# HTNB32L-XXX register map
File version: 0.9
CPU: CM3 r0p0, little endian, no MPU, no FPU, 3 interrupt priority bits
Registers are 32-bit, read-write, reset 0x0 unless marked. A register's access mark holds for its fields unless they carry their own. Offsets are from the block's base; [hi:lo] are bit positions; 'fields as' and 'values as' point back to an identical list.

## IOCON (part 1 of 3) — IOCON pin configuration
Base 0x4002C000
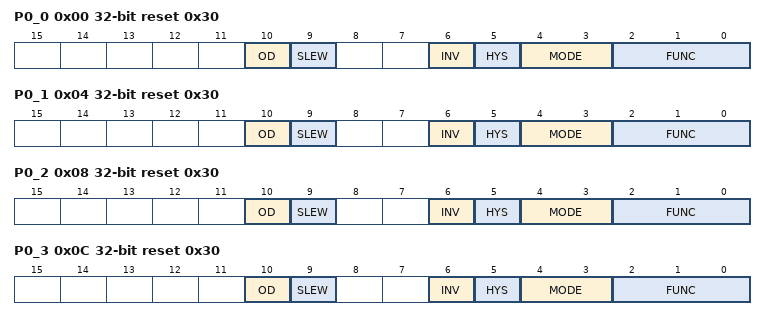
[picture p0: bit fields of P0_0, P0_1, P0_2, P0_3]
0x00 P0_0 reset 0x30 — I/O configuration register for pin P0[0]
  [10] OD — Open-drain mode.
    0=DISABLE; 1=ENABLED (Open-drain mode enabled. This is not a true open-drain mode. Input cannot be pulled up above VDD.)
  [9] SLEW — Driver slew rate
    0=STANDARD (Standard mode, output slew rate control is enabled. More outputs can be switched simultaneously.); 1=FAST (Fast mode, slew rate control is disabled. Refer to the appropriate specific device data sheet for details.)
  [6] INV — Invert input
    0=INPUT_NOT_INVERTED (Input not inverted (HIGH on pin reads as 1, LOW on pin reads as 0).); 1=INPUT_INVERTED_HIGH (Input inverted (HIGH on pin reads as 0, LOW on pin reads as 1).)
  [5] HYS — Hysteresis.
    0=DISABLE; 1=ENABLE
  [4:3] MODE — Selects function mode (on-chip pull-up/pull-down resistor control).
    0=INACTIVE (Inactive (no pull-down/pull-up resistor enabled).); 1=PULLDOWN_EN (Pull-down resistor enabled.); 2=PULLUP_EN (Pull-up resistor enabled.); 3=REPEATER_MODE
  [2:0] FUNC — Selects pin function for pin P0[0]
    0=P0_0 (General purpose digital input/output pin.); 1=CAN_RD1 (CAN1 receiver input.); 2=U3_TXD (Transmitter output for UART3.); 3=I2C1_SDA (I2C1 data input/output(this pin does not use a specialized I2C pad).); 4=U0_TXD (Transmitter output for UART0.)
0x04 P0_1 reset 0x30 — I/O configuration register for pin P0[1]
  [10] OD — Open-drain mode.
    values as P0_0.OD
  [9] SLEW — Driver slew rate
    values as P0_0.SLEW
  [6] INV — Invert input
    values as P0_0.INV
  [5] HYS — Hysteresis.
    0=DISABLE; 1=ENABLE
  [4:3] MODE — Selects function mode (on-chip pull-up/pull-down resistor control).
    values as P0_0.MODE
  [2:0] FUNC — Selects pin function for pin P0[1]
    0=P0_1 (General purpose digital input/output pin.); 1=CAN_TD1 (CAN1 transmitter output.); 2=U3_RXD (Receiver input for UART3.); 3=I2C1_SCL (I2C1 clock input/output (this pin does not use a specialized I2C pad).); 4=U0_RXD (Receiver input for UART0.)
0x08 P0_2 reset 0x30 — I/O configuration register for pin P0[2]
  [10] OD — Open-drain mode.
    values as P0_0.OD
  [9] SLEW — Driver slew rate
    values as P0_0.SLEW
  [6] INV — Invert input
    values as P0_0.INV
  [5] HYS — Hysteresis.
    0=DISABLE; 1=ENABLE
  [4:3] MODE — Selects function mode (on-chip pull-up/pull-down resistor control).
    values as P0_0.MODE
  [2:0] FUNC — Selects pin function for pin P0[2]
    0=P0_2 (General purpose digital input/output pin.); 1=U0_TXD (Transmitter output for UART0.); 2=U3_TXD (Transmitter output for UART3.)
0x0C P0_3 reset 0x30 — I/O configuration register for pin P0[3]
  [10] OD — Open-drain mode.
    values as P0_0.OD
  [9] SLEW — Driver slew rate
    values as P0_0.SLEW
  [6] INV — Invert input
    values as P0_0.INV
  [5] HYS — Hysteresis.
    0=DISABLE; 1=ENABLE
  [4:3] MODE — Selects function mode (on-chip pull-up/pull-down resistor control).
    values as P0_0.MODE
  [2:0] FUNC — Selects pin function for pin P0[3]
    0=P0_3 (General purpose digital input/output pin.); 1=U0_RXD (Receiver input for UART0.); 2=U3_RXD (Receiver input for UART3.)
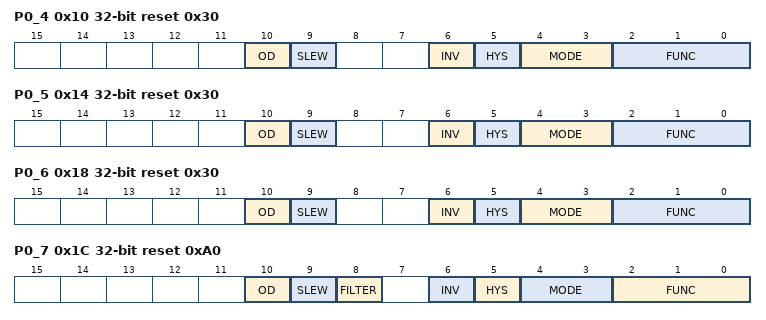
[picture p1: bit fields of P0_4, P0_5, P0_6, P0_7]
0x10 P0_4 reset 0x30 — I/O configuration register for pin P0[4]
  [10] OD — Open-drain mode.
    values as P0_0.OD
  [9] SLEW — Driver slew rate
    values as P0_0.SLEW
  [6] INV — Invert input
    values as P0_0.INV
  [5] HYS — Hysteresis.
    0=DISABLE; 1=ENABLE
  [4:3] MODE — Selects function mode (on-chip pull-up/pull-down resistor control).
    values as P0_0.MODE
  [2:0] FUNC — Selects pin function for pin P0[4]
    0=P0_4 (General purpose digital input/output pin.); 1=I2S_RX_SCK (I2S Receive clock. It is driven by the master and received by the slave. Corresponds to the signal SCK in the I2S-bus specification.); 2=CAN_RD2 (CAN2 receiver input.); 3=T2_CAP0 (Capture input for Timer 2, channel 0.); 7=LCD_VD_0 (LCD data.)
0x14 P0_5 reset 0x30 — I/O configuration register for pin P0[5]
  [10] OD — Open-drain mode.
    values as P0_0.OD
  [9] SLEW — Driver slew rate
    values as P0_0.SLEW
  [6] INV — Invert input
    values as P0_0.INV
  [5] HYS — Hysteresis.
    0=DISABLE; 1=ENABLE
  [4:3] MODE — Selects function mode (on-chip pull-up/pull-down resistor control).
    values as P0_0.MODE
  [2:0] FUNC — Selects pin function for pin P0[5]
    0=P0_5 (General purpose digital input/output pin.); 1=I2S_RX_WS (I2S Receive word select. It is driven by the master and received by the slave. Corresponds to the signal WS in the I2S-bus specification.); 2=CAN_TD2 (CAN2 transmitter output.); 3=T2_CAP1 (Capture input for Timer 2, channel 1.); 7=LCD_VD_1 (LCD data.)
0x18 P0_6 reset 0x30 — I/O configuration register for pin P0[6]
  [10] OD — Open-drain mode.
    values as P0_0.OD
  [9] SLEW — Driver slew rate
    values as P0_0.SLEW
  [6] INV — Invert input
    values as P0_0.INV
  [5] HYS — Hysteresis.
    0=DISABLE; 1=ENABLE
  [4:3] MODE — Selects function mode (on-chip pull-up/pull-down resistor control).
    values as P0_0.MODE
  [2:0] FUNC — Selects pin function for pin P0[6]
    0=P0_6 (General purpose digital input/output pin.); 1=I2S_RX_SDA (I2S Receive data. It is driven by the transmitter and read by the receiver. Corresponds to the signal SD in the I2S-bus specification.); 2=SSP1_SSEL (Slave Select for SSP1.); 3=T2_MAT0 (Match output for Timer 2, channel 0.); 4=U1_RTS (Request to Send output for UART1. Can also be configured to be an RS-485/EIA-485 output enable signal for UART1.); 7=LCD_VD_8 (LCD data.)
0x1C P0_7 reset 0xA0 — I/O configuration register for pin P0[7]
  [10] OD — Open-drain mode.
    values as P0_0.OD
  [9] SLEW — Driver slew rate
    values as P0_0.SLEW
  [8] FILTER — Glitch filter control
    0=ENABLED (Noise pulses below approximately 10 ns are filtered out.); 1=DISABLED (No input filtering is done.)
  [6] INV — Invert input
    values as P0_0.INV
  [5] HYS — Hysteresis.
    0=DISABLE; 1=ENABLE
  [4:3] MODE — Selects function mode (on-chip pull-up/pull-down resistor control).
    values as P0_0.MODE
  [2:0] FUNC — Selects pin function for pin P0[7]
    0=P0_7 (General purpose digital input/output pin.); 1=I2S_TX_SCK (I2S transmit clock. It is driven by the master and received by the slave. Corresponds to the signal SCK in the I2S-bus specification.); 2=SSP1_SCK (Serial Clock for SSP1.); 3=T2_MAT1 (Match output for Timer 2, channel 1.); 4=RTC_EV0 (Event input 0 to Event Monitor/Recorder.); 7=LCD_VD_9 (LCD data.)
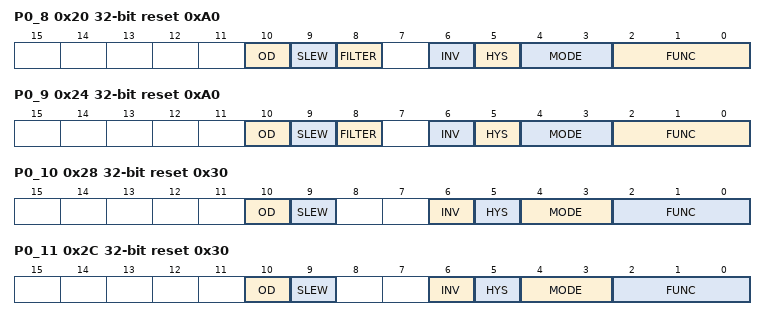
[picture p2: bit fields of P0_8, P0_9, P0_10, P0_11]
0x20 P0_8 reset 0xA0 — I/O configuration register for pin P0[8]
  [10] OD — Open-drain mode.
    values as P0_0.OD
  [9] SLEW — Driver slew rate
    values as P0_0.SLEW
  [8] FILTER — Glitch filter control
    values as P0_7.FILTER
  [6] INV — Invert input
    values as P0_0.INV
  [5] HYS — Hysteresis.
    0=DISABLE; 1=ENABLE
  [4:3] MODE — Selects function mode (on-chip pull-up/pull-down resistor control).
    values as P0_0.MODE
  [2:0] FUNC — Selects pin function for pin P0[8]
    0=P0_8 (General purpose digital input/output pin.); 1=I2S_TX_WS (I2S Transmit word select. It is driven by the master and received by the slave. Corresponds to the signal WS in the I2S-bus specification.); 2=SSP1_MISO (Master In Slave Out for SSP1.); 3=T2_MAT2 (Match output for Timer 2, channel 2.); 4=RTC_EV1 (Event input 1 to Event Monitor/Recorder.); 7=LCD_VD_16 (LCD data.)
0x24 P0_9 reset 0xA0 — I/O configuration register for pin P0[9]
  [10] OD — Open-drain mode.
    values as P0_0.OD
  [9] SLEW — Driver slew rate
    values as P0_0.SLEW
  [8] FILTER — Glitch filter control
    values as P0_7.FILTER
  [6] INV — Invert input
    values as P0_0.INV
  [5] HYS — Hysteresis.
    0=DISABLE; 1=ENABLE
  [4:3] MODE — Selects function mode (on-chip pull-up/pull-down resistor control).
    values as P0_0.MODE
  [2:0] FUNC — Selects pin function for pin P0[9]
    0=P0_9 (General purpose digital input/output pin.); 1=I2S_TX_SDA (I2S transmit data. It is driven by the transmitter and read by the receiver. Corresponds to the signal SD in the I2S-bus specification.); 2=SSP1_MOSI (Master Out Slave In for SSP1.); 3=T2_MAT3 (Match output for Timer 2, channel 3.); 4=RTC_EV2 (Event input 2 to Event Monitor/Recorder.); 7=LCD_VD_17 (LCD data.)
0x28 P0_10 reset 0x30 — I/O configuration register for pin P0[10]
  [10] OD — Open-drain mode.
    values as P0_0.OD
  [9] SLEW — Driver slew rate
    values as P0_0.SLEW
  [6] INV — Invert input
    values as P0_0.INV
  [5] HYS — Hysteresis.
    0=DISABLE; 1=ENABLE
  [4:3] MODE — Selects function mode (on-chip pull-up/pull-down resistor control).
    values as P0_0.MODE
  [2:0] FUNC — Selects pin function for pin P0[10]
    0=P0_10 (General purpose digital input/output pin.); 1=U2_TXD (Transmitter output for UART2.); 2=I2C2_SDA (I2C2 data input/output (this pin does not use a specialized I2C pad).); 3=T3_MAT0 (Match output for Timer 3, channel 0.)
0x2C P0_11 reset 0x30 — I/O configuration register for pin P0[11]
  [10] OD — Open-drain mode.
    values as P0_0.OD
  [9] SLEW — Driver slew rate
    values as P0_0.SLEW
  [6] INV — Invert input
    values as P0_0.INV
  [5] HYS — Hysteresis.
    0=DISABLE; 1=ENABLE
  [4:3] MODE — Selects function mode (on-chip pull-up/pull-down resistor control).
    values as P0_0.MODE
  [2:0] FUNC — Selects pin function for pin P0[11]
    0=P0_11 (General purpose digital input/output pin.); 1=U2_RXD (Receiver input for UART2.); 2=I2C2_SCL (I2C2 clock input/output (this pin does not use a specialized I2C pad).); 3=T3_MAT1 (Match output for Timer 3, channel 1.)
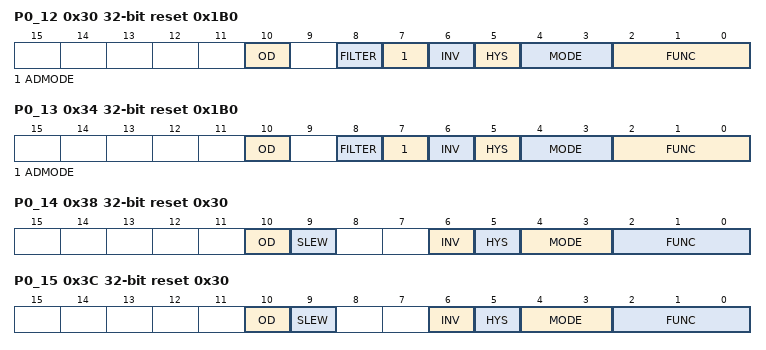
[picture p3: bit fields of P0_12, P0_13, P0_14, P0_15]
0x30 P0_12 reset 0x1B0 — I/O configuration register for pin P0[12]
  [10] OD — Open-drain mode.
    0=DISABLE; 1=ENABLED (Open-drain mode enabled. This is not a true open-drain mode.)
  [8] FILTER — Selects 10 ns input glitch filter.
    0=FILTER_DISABLED; 1=FILTER_ENABLED
  [7] ADMODE — Selects Analog/Digital mode.
    0=ANALOG_INPUT_MODE; 1=DIGITAL_FUNCTIONAL_M (Digital functional mode.)
  [6] INV — Invert input
    values as P0_0.INV
  [5] HYS — Hysteresis.
    0=DISABLE; 1=ENABLE
  [4:3] MODE — Selects function mode (on-chip pull-up/pull-down resistor control).
    values as P0_0.MODE
  [2:0] FUNC — Selects pin function for pin P0[12]
    0=P0_12 (General purpose digital input/output pin.); 1=USB_PPWR2 (Port Power enable signal for USB port 2.); 2=SSP1_MISO (Master In Slave Out for SSP1.); 3=ADC0_IN_6 (A/D converter 0, input 6. When configured as an ADC input, the digital function of the pin must be disabled.)
0x34 P0_13 reset 0x1B0 — I/O configuration register for pin P0[13]
  [10] OD — Open-drain mode.
    values as P0_12.OD
  [8] FILTER — Selects 10 ns input glitch filter.
    0=FILTER_DISABLED; 1=FILTER_ENABLED
  [7] ADMODE — Selects Analog/Digital mode.
    values as P0_12.ADMODE
  [6] INV — Invert input
    values as P0_0.INV
  [5] HYS — Hysteresis.
    0=DISABLE; 1=ENABLE
  [4:3] MODE — Selects function mode (on-chip pull-up/pull-down resistor control).
    values as P0_0.MODE
  [2:0] FUNC — Selects pin function for pin P0[13]
    0=P0_13 (General purpose digital input/output pin.); 1=USB_UP_LED2 (USB port 2 GoodLink LED indicator. It is LOW when the device is configured (non-control endpoints enabled), or when the host is enabled and has detected a device on the bus. It is HIGH when the device is not configured, or when host is enabled and has not detected a device on the bus, or during global suspend. It transitions between LOW and HIGH (flashes) when the host is enabled and detects activity on the bus.); 2=SSP1_MOSI (Master Out Slave In for SSP1.); 3=ADC0_IN_7 (A/D converter 0, input 7. When configured as an ADC input, the digital function of the pin must be disabled.)
0x38 P0_14 reset 0x30 — I/O configuration register for pin P0[14]
  [10] OD — Open-drain mode.
    values as P0_0.OD
  [9] SLEW — Driver slew rate
    values as P0_0.SLEW
  [6] INV — Invert input
    values as P0_0.INV
  [5] HYS — Hysteresis.
    0=DISABLE; 1=ENABLE
  [4:3] MODE — Selects function mode (on-chip pull-up/pull-down resistor control).
    values as P0_0.MODE
  [2:0] FUNC — Selects pin function for pin P0[14]
    0=P0_14 (General purpose digital input/output pin.); 1=USB_HSTEN2 (Host Enabled status for USB port 2.); 2=SSP1_SSEL (Slave Select for SSP1.); 3=USB_CONNECT2 (SoftConnect control for USB port 2. Signal used to switch an external 1.5 kW resistor under software control. Used with the SoftConnect USB feature.)
0x3C P0_15 reset 0x30 — I/O configuration register for pin P0[15]
  [10] OD — Open-drain mode.
    values as P0_0.OD
  [9] SLEW — Driver slew rate
    values as P0_0.SLEW
  [6] INV — Invert input
    values as P0_0.INV
  [5] HYS — Hysteresis.
    0=DISABLE; 1=ENABLE
  [4:3] MODE — Selects function mode (on-chip pull-up/pull-down resistor control).
    values as P0_0.MODE
  [2:0] FUNC — Selects pin function for pin P0[15]
    0=P0_15 (General purpose digital input/output pin.); 1=U1_TXD (Transmitter output for UART1.); 2=SSP0_SCK (Serial clock for SSP0.)
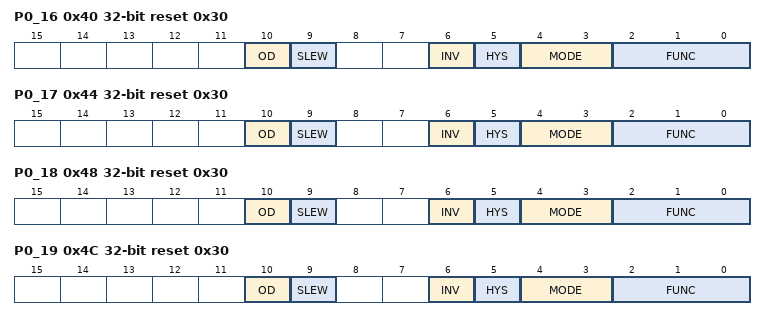
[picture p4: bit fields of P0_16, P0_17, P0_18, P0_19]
0x40 P0_16 reset 0x30 — I/O configuration register for pin P0[16]
  [10] OD — Open-drain mode.
    values as P0_0.OD
  [9] SLEW — Driver slew rate
    values as P0_0.SLEW
  [6] INV — Invert input
    values as P0_0.INV
  [5] HYS — Hysteresis.
    0=DISABLE; 1=ENABLE
  [4:3] MODE — Selects function mode (on-chip pull-up/pull-down resistor control).
    values as P0_0.MODE
  [2:0] FUNC — Selects pin function for pin P0[16]
    0=P0_16 (General purpose digital input/output pin.); 1=U1_RXD (Receiver input for UART1.); 2=SSP0_SSEL (Slave Select for SSP0.)
0x44 P0_17 reset 0x30 — I/O configuration register for pin P0[17]
  [10] OD — Open-drain mode.
    values as P0_0.OD
  [9] SLEW — Driver slew rate
    values as P0_0.SLEW
  [6] INV — Invert input
    values as P0_0.INV
  [5] HYS — Hysteresis.
    0=DISABLE; 1=ENABLE
  [4:3] MODE — Selects function mode (on-chip pull-up/pull-down resistor control).
    values as P0_0.MODE
  [2:0] FUNC — Selects pin function for pin P0[17]
    0=P0_17 (General purpose digital input/output pin.); 1=U1_CTS (Clear to Send input for UART1.); 2=SSP0_MISO (Master In Slave Out for SSP0.)
0x48 P0_18 reset 0x30 — I/O configuration register for pin P0[18]
  [10] OD — Open-drain mode.
    values as P0_0.OD
  [9] SLEW — Driver slew rate
    values as P0_0.SLEW
  [6] INV — Invert input
    values as P0_0.INV
  [5] HYS — Hysteresis.
    0=DISABLE; 1=ENABLE
  [4:3] MODE — Selects function mode (on-chip pull-up/pull-down resistor control).
    values as P0_0.MODE
  [2:0] FUNC — Selects pin function for pin P0[18]
    0=P0_18 (General purpose digital input/output pin.); 1=U1_DCD (Data Carrier Detect input for UART1.); 2=SSP0_MOSI (Master Out Slave In for SSP0.)
0x4C P0_19 reset 0x30 — I/O configuration register for pin P0[19]
  [10] OD — Open-drain mode.
    values as P0_0.OD
  [9] SLEW — Driver slew rate
    values as P0_0.SLEW
  [6] INV — Invert input
    values as P0_0.INV
  [5] HYS — Hysteresis.
    0=DISABLE; 1=ENABLE
  [4:3] MODE — Selects function mode (on-chip pull-up/pull-down resistor control).
    values as P0_0.MODE
  [2:0] FUNC — Selects pin function for pin P0[19]
    0=P0_19 (General purpose digital input/output pin.); 1=U1_DSR (Data Set Ready input for UART1.); 2=SD_CLK (Clock output line for SD card interface.); 3=I2C1_SDA (I2C1 data input/output (this pin does not use a specialized I2C pad).)
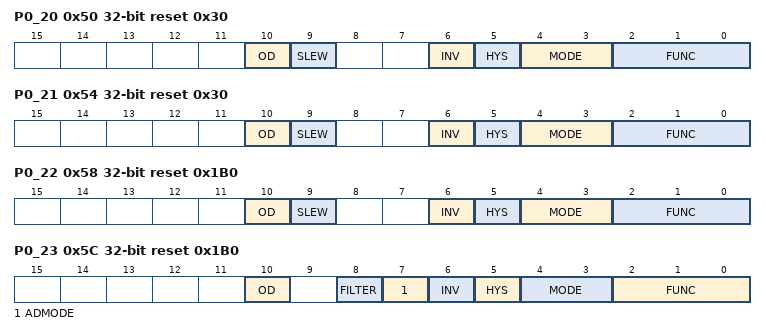
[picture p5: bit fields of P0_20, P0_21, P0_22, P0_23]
0x50 P0_20 reset 0x30 — I/O configuration register for pin P0[20]
  [10] OD — Open-drain mode.
    values as P0_0.OD
  [9] SLEW — Driver slew rate
    values as P0_0.SLEW
  [6] INV — Invert input
    values as P0_0.INV
  [5] HYS — Hysteresis.
    0=DISABLE; 1=ENABLE
  [4:3] MODE — Selects function mode (on-chip pull-up/pull-down resistor control).
    values as P0_0.MODE
  [2:0] FUNC — Selects pin function for pin P0[20]
    0=P0_20 (General purpose digital input/output pin.); 1=U1_DTR (Data Terminal Ready output for UART1. Can also be configured to be an RS-485/EIA-485 output enable signal for UART1.); 2=SD_CMD (Command line for SD card interface.); 3=I2C1_SCL (I2C1 clock input/output (this pin does not use a specialized I2C pad).)
0x54 P0_21 reset 0x30 — I/O configuration register for pin P0[21]
  [10] OD — Open-drain mode.
    values as P0_0.OD
  [9] SLEW — Driver slew rate
    values as P0_0.SLEW
  [6] INV — Invert input
    values as P0_0.INV
  [5] HYS — Hysteresis.
    0=DISABLE; 1=ENABLE
  [4:3] MODE — Selects function mode (on-chip pull-up/pull-down resistor control).
    values as P0_0.MODE
  [2:0] FUNC — Selects pin function for pin P0[21]
    0=P0_21 (General purpose digital input/output pin.); 1=U1_RI (Ring Indicator input for UART1.); 2=SD_PWR (Power Supply Enable for external SD card power supply.); 3=U4_OE (RS-485/EIA-485 output enable signal for UART4.); 4=CAN_RD1 (CAN1 receiver input.); 5=U4_SCLK (USART 4 clock input or output in synchronous mode.)
0x58 P0_22 reset 0x1B0 — I/O configuration register for pin P0[22]
  [10] OD — Open-drain mode.
    values as P0_0.OD
  [9] SLEW — Driver slew rate
    values as P0_0.SLEW
  [6] INV — Invert input
    values as P0_0.INV
  [5] HYS — Hysteresis.
    0=DISABLE; 1=ENABLE
  [4:3] MODE — Selects function mode (on-chip pull-up/pull-down resistor control).
    values as P0_0.MODE
  [2:0] FUNC — Selects pin function for pin P0[22]
    0=P0_22 (General purpose digital input/output pin.); 1=U1_RTS (Request to Send output for UART1. Can also be configured to be an RS-485/EIA-485 output enable signal for UART1.); 2=SD_DAT_0 (Data line 0 for SD card interface.); 3=U4_TXD (Transmitter output for USART4 (input/output in smart card mode).); 4=CAN_TD1 (CAN1 transmitter output.)
0x5C P0_23 reset 0x1B0 — I/O configuration register for pin P0[23]
  [10] OD — Open-drain mode.
    values as P0_12.OD
  [8] FILTER — Selects 10 ns input glitch filter.
    0=FILTER_DISABLED; 1=FILTER_ENABLED
  [7] ADMODE — Selects Analog/Digital mode.
    values as P0_12.ADMODE
  [6] INV — Invert input
    values as P0_0.INV
  [5] HYS — Hysteresis.
    0=DISABLE; 1=ENABLE
  [4:3] MODE — Selects function mode (on-chip pull-up/pull-down resistor control).
    values as P0_0.MODE
  [2:0] FUNC — Selects pin function for pin P0[23]
    0=P0_23 (General purpose digital input/output pin.); 1=ADC0_IN_0 (A/D converter 0, input 0. When configured as an ADC input, the digital function of the pin must be disabled.); 2=I2S_RX_SCK (Receive Clock. It is driven by the master and received by the slave. Corresponds to the signal SCK in the I2S-bus specification.); 3=T3_CAP0 (Capture input for Timer 3, channel 0.)
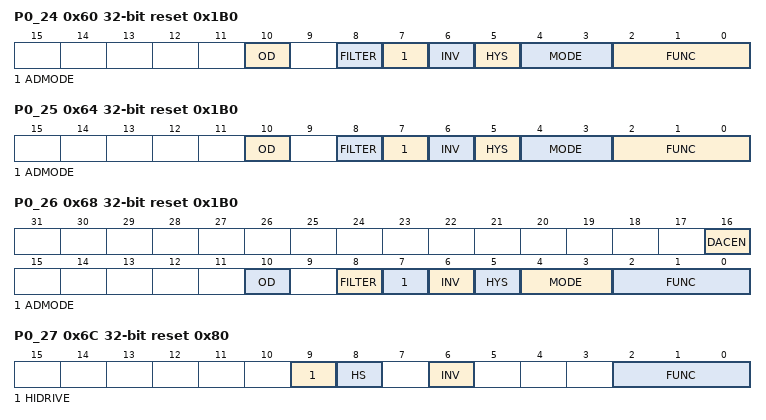
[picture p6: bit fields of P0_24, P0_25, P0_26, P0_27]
0x60 P0_24 reset 0x1B0 — I/O configuration register for pin P0[24]
  [10] OD — Open-drain mode.
    values as P0_12.OD
  [8] FILTER — Selects 10 ns input glitch filter.
    0=FILTER_DISABLED; 1=FILTER_ENABLED
  [7] ADMODE — Selects Analog/Digital mode.
    values as P0_12.ADMODE
  [6] INV — Invert input
    values as P0_0.INV
  [5] HYS — Hysteresis.
    0=DISABLE; 1=ENABLE
  [4:3] MODE — Selects function mode (on-chip pull-up/pull-down resistor control).
    values as P0_0.MODE
  [2:0] FUNC — Selects pin function for pin P0[24]
    0=P0_24 (General purpose digital input/output pin.); 1=ADC0_IN_1 (A/D converter 0, input 1. When configured as an ADC input, the digital function of the pin must be disabled.); 2=I2S_RX_WS (Receive Word Select. It is driven by the master and received by the slave. Corresponds to the signal WS in the I2S-bus specification.); 3=T3_CAP1 (Capture input for Timer 3, channel 1.)
0x64 P0_25 reset 0x1B0 — I/O configuration register for pin P0[25]
  [10] OD — Open-drain mode.
    values as P0_12.OD
  [8] FILTER — Selects 10 ns input glitch filter.
    0=FILTER_DISABLED; 1=FILTER_ENABLED
  [7] ADMODE — Selects Analog/Digital mode.
    values as P0_12.ADMODE
  [6] INV — Invert input
    values as P0_0.INV
  [5] HYS — Hysteresis.
    0=DISABLE; 1=ENABLE
  [4:3] MODE — Selects function mode (on-chip pull-up/pull-down resistor control).
    values as P0_0.MODE
  [2:0] FUNC — Selects pin function for pin P0[25]
    0=P0_25 (General purpose digital input/output pin.); 1=ADC0_IN_2 (A/D converter 0, input 2. When configured as an ADC input, the digital function of the pin must be disabled.); 2=I2S_RX_SDA (Receive data. It is driven by the transmitter and read by the receiver. Corresponds to the signal SD in the I2S-bus specification.); 3=U3_TXD (Transmitter output for UART3.)
0x68 P0_26 reset 0x1B0 — I/O configuration register for pin P0[26]
  [16] DACEN — DAC output enable.
    0=DISABLE (DAC disable.); 1=ENABLE (DAC enable.)
  [10] OD — Open-drain mode.
    values as P0_12.OD
  [8] FILTER — Selects 10 ns input glitch filter.
    0=FILTER_DISABLED; 1=FILTER_ENABLED
  [7] ADMODE — Selects Analog/Digital mode.
    values as P0_12.ADMODE
  [6] INV — Invert input
    values as P0_0.INV
  [5] HYS — Hysteresis.
    0=DISABLE; 1=ENABLE
  [4:3] MODE — Selects function mode (on-chip pull-up/pull-down resistor control).
    values as P0_0.MODE
  [2:0] FUNC — Selects pin function for pin P0[26]
    0=P0_26 (General purpose digital input/output pin.); 1=ADC0_IN_3 (A/D converter 0, input 3. When configured as an ADC input, the digital function of the pin must be disabled.); 2=DAC_OUT (D/A converter output. When configured as the DAC output, the digital function of the pin must be disabled.); 3=U3_RXD (Receiver input for UART3.)
0x6C P0_27 reset 0x80 — I/O configuration register for pin P0[27]
  [9] HIDRIVE — Controls sink current capability of the pin, only for P5[2] and P5[3].
    0=LOWDRIVE (Output drive sink is 4 mA. This is sufficient for standard and fast mode I2C.); 1=HIGHDRIVE (Output drive sink is 20 mA. This is needed for Fast Mode Plus I2C. Refer to the appropriate specific device data sheet for details.)
  [8] HS — Configures I2C features for standard mode, fast mode, and Fast Mode Plus operation.
    0=ENABLED (I2C 50ns glitch filter and slew rate control enabled.); 1=DISABLED (I2C 50ns glitch filter and slew rate control disabled.)
  [6] INV — Invert input
    values as P0_0.INV
  [2:0] FUNC — Selects pin function for pin P0[27]
    0=P0_27 (General purpose digital input/output pin.); 1=I2C0_SDA (I2C0 data input/output. (This pin uses a specialized I2C pad).); 2=USB_SDA1 (I2C serial data for communication with an external USB transceiver.)
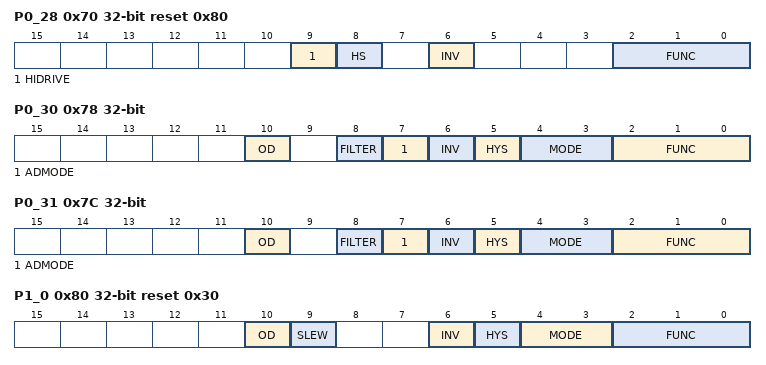
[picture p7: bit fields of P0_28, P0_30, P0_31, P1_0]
0x70 P0_28 reset 0x80 — I/O configuration register for pin P0[28]
  [9] HIDRIVE — Controls sink current capability of the pin, only for P5[2] and P5[3].
    values as P0_27.HIDRIVE
  [8] HS — Configures I2C features for standard mode, fast mode, and Fast Mode Plus operation.
    values as P0_27.HS
  [6] INV — Invert input
    values as P0_0.INV
  [2:0] FUNC — Selects pin function for pin P0[28]
    0=P0_28 (General purpose digital input/output pin.); 1=I2C0_SCL (I2C0 clock input/output (this pin uses a specialized I2C pad.); 2=USB_SCL1 (I2C serial clock for communication with an external USB transceiver.)
0x74 P0_29 — I/O configuration register for pin P0[29]
  [2:0] FUNC — Selects pin function for pin P0[29]
    0=P0_29 (General purpose digital input/output pin.); 1=USB_DP1 (USB port 1 bidirectional D+ line.); 2=EINT0 (External interrupt 0 input.)
0x78 P0_30 — I/O configuration register for pin P0[30]
  [10] OD — Open-drain mode.
    values as P0_12.OD
  [8] FILTER — Selects 10 ns input glitch filter.
    0=FILTER_DISABLED; 1=FILTER_ENABLED
  [7] ADMODE — Selects Analog/Digital mode.
    values as P0_12.ADMODE
  [6] INV — Invert input
    values as P0_0.INV
  [5] HYS — Hysteresis.
    0=DISABLE; 1=ENABLE
  [4:3] MODE — Selects function mode (on-chip pull-up/pull-down resistor control).
    values as P0_0.MODE
  [2:0] FUNC — Selects pin function for pin P0[30]
    0=P0_30 (General purpose digital input/output pin.); 1=USB_DM1 (USB port 1 bidirectional D- line.); 2=EINT1 (External interrupt 1 input.)
0x7C P0_31 — I/O configuration register for pin P0[31]
  [10] OD — Open-drain mode.
    values as P0_12.OD
  [8] FILTER — Selects 10 ns input glitch filter.
    0=FILTER_DISABLED; 1=FILTER_ENABLED
  [7] ADMODE — Selects Analog/Digital mode.
    values as P0_12.ADMODE
  [6] INV — Invert input
    values as P0_0.INV
  [5] HYS — Hysteresis.
    0=DISABLE; 1=ENABLE
  [4:3] MODE — Selects function mode (on-chip pull-up/pull-down resistor control).
    values as P0_0.MODE
  [2:0] FUNC — Selects pin function for pin P0[31]
    0=P0_31 (General purpose digital input/output pin.); 1=USB_DP2 (USB port 2 bidirectional D+ line.)
0x80 P1_0 reset 0x30 — I/O configuration register for pin P1[0]
  [10] OD — Open-drain mode.
    values as P0_0.OD
  [9] SLEW — Driver slew rate
    values as P0_0.SLEW
  [6] INV — Invert input
    values as P0_0.INV
  [5] HYS — Hysteresis.
    0=DISABLE; 1=ENABLE
  [4:3] MODE — Selects function mode (on-chip pull-up/pull-down resistor control).
    values as P0_0.MODE
  [2:0] FUNC — Selects pin function for pin P1[0]
    0=P1_0 (General purpose digital input/output pin.); 1=ENET_TXD0 (Ethernet transmit data 0 (RMII/MII interface).); 3=T3_CAP1 (Capture input for Timer 3, channel 1.); 4=SSP2_SCK (Serial clock for SSP2.)
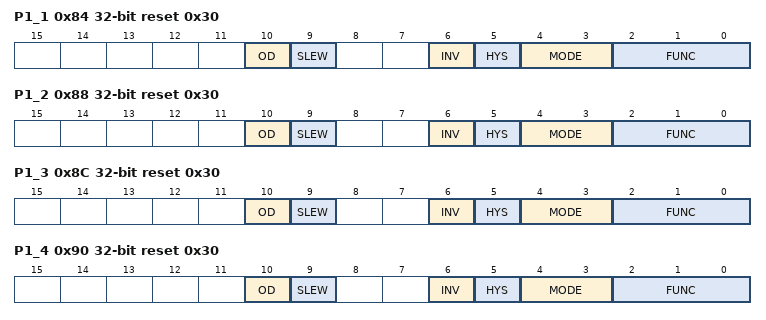
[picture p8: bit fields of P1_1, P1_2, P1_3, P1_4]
0x84 P1_1 reset 0x30 — I/O configuration register for pin P1[1]
  [10] OD — Open-drain mode.
    values as P0_0.OD
  [9] SLEW — Driver slew rate
    values as P0_0.SLEW
  [6] INV — Invert input
    values as P0_0.INV
  [5] HYS — Hysteresis.
    0=DISABLE; 1=ENABLE
  [4:3] MODE — Selects function mode (on-chip pull-up/pull-down resistor control).
    values as P0_0.MODE
  [2:0] FUNC — Selects pin function for pin P1[1]
    0=P1_1 (General purpose digital input/output pin.); 1=ENET_TXD1 (Ethernet transmit data 1 (RMII/MII interface).); 3=T3_MAT3 (Match output for Timer 3, channel 3.); 4=SSP2_MOSI (Master Out Slave In for SSP2.)
0x88 P1_2 reset 0x30 — I/O configuration register for pin P1[2]
  [10] OD — Open-drain mode.
    values as P0_0.OD
  [9] SLEW — Driver slew rate
    values as P0_0.SLEW
  [6] INV — Invert input
    values as P0_0.INV
  [5] HYS — Hysteresis.
    0=DISABLE; 1=ENABLE
  [4:3] MODE — Selects function mode (on-chip pull-up/pull-down resistor control).
    values as P0_0.MODE
  [2:0] FUNC — Selects pin function for pin P1[2]
    0=P1_2 (General purpose digital input/output pin.); 1=ENET_TXD2 (Ethernet transmit data 2 (MII interface).); 2=SD_CLK (Clock output line for SD card interface.); 3=PWM0_1 (Pulse Width Modulator 0, output 1.)
0x8C P1_3 reset 0x30 — I/O configuration register for pin P1[3]
  [10] OD — Open-drain mode.
    values as P0_0.OD
  [9] SLEW — Driver slew rate
    values as P0_0.SLEW
  [6] INV — Invert input
    values as P0_0.INV
  [5] HYS — Hysteresis.
    0=DISABLE; 1=ENABLE
  [4:3] MODE — Selects function mode (on-chip pull-up/pull-down resistor control).
    values as P0_0.MODE
  [2:0] FUNC — Selects pin function for pin P1[3]
    0=P1_3 (General purpose digital input/output pin.); 1=ENET_TXD3 (Ethernet transmit data 3 (MII interface).); 2=SD_CMD (Command line for SD card interface.); 3=PWM0_2 (Pulse Width Modulator 0, output 2.)
0x90 P1_4 reset 0x30 — I/O configuration register for pin P1[4]
  [10] OD — Open-drain mode.
    values as P0_0.OD
  [9] SLEW — Driver slew rate
    values as P0_0.SLEW
  [6] INV — Invert input
    values as P0_0.INV
  [5] HYS — Hysteresis.
    0=DISABLE; 1=ENABLE
  [4:3] MODE — Selects function mode (on-chip pull-up/pull-down resistor control).
    values as P0_0.MODE
  [2:0] FUNC — Selects pin function for pin P1[4]
    0=P1_4 (General purpose digital input/output pin.); 1=ENET_TX_EN (Ethernet transmit data enable (RMII/MII interface).); 3=T3_MAT2 (Match output for Timer 3, channel 2.); 4=SSP2_MISO (Master In Slave Out for SSP2.)
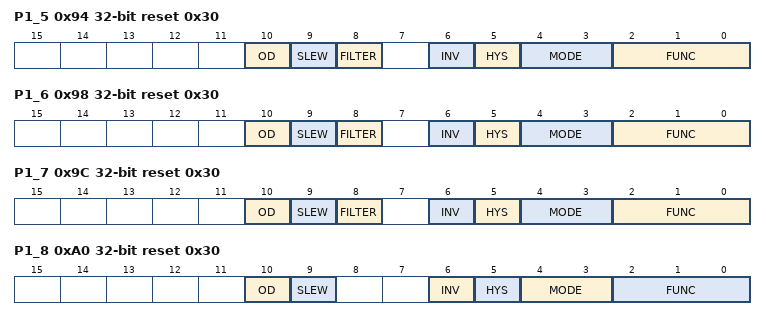
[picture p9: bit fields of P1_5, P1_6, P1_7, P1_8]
0x94 P1_5 reset 0x30 — I/O configuration register for pin P1[5]
  [10] OD — Open-drain mode.
    values as P0_0.OD
  [9] SLEW — Driver slew rate
    values as P0_0.SLEW
  [8] FILTER — Glitch filter control
    values as P0_7.FILTER
  [6] INV — Invert input
    values as P0_0.INV
  [5] HYS — Hysteresis.
    0=DISABLE; 1=ENABLE
  [4:3] MODE — Selects function mode (on-chip pull-up/pull-down resistor control).
    values as P0_0.MODE
  [2:0] FUNC — Selects pin function for pin P1[5]
    0=P1_5 (General purpose digital input/output pin.); 1=ENET_TX_ER (Ethernet Transmit Error (MII interface).); 2=SD_PWR (Power Supply Enable for external SD card power supply.); 3=PWM0_3 (Pulse Width Modulator 0, output 3.)
0x98 P1_6 reset 0x30 — I/O configuration register for pin P1[6]
  [10] OD — Open-drain mode.
    values as P0_0.OD
  [9] SLEW — Driver slew rate
    values as P0_0.SLEW
  [8] FILTER — Glitch filter control
    values as P0_7.FILTER
  [6] INV — Invert input
    values as P0_0.INV
  [5] HYS — Hysteresis.
    0=DISABLE; 1=ENABLE
  [4:3] MODE — Selects function mode (on-chip pull-up/pull-down resistor control).
    values as P0_0.MODE
  [2:0] FUNC — Selects pin function for pin P1[6]
    0=P1_6 (General purpose digital input/output pin.); 1=ENET_TX_CLK (Ethernet Transmit Clock (MII interface).); 2=SD_DAT_0 (Data line 0 for SD card interface.); 3=PWM0_4 (Pulse Width Modulator 0, output 4.)
0x9C P1_7 reset 0x30 — I/O configuration register for pin P1[7]
  [10] OD — Open-drain mode.
    values as P0_0.OD
  [9] SLEW — Driver slew rate
    values as P0_0.SLEW
  [8] FILTER — Glitch filter control
    values as P0_7.FILTER
  [6] INV — Invert input
    values as P0_0.INV
  [5] HYS — Hysteresis.
    0=DISABLE; 1=ENABLE
  [4:3] MODE — Selects function mode (on-chip pull-up/pull-down resistor control).
    values as P0_0.MODE
  [2:0] FUNC — Selects pin function for pin P1[7]
    0=P1_7 (General purpose digital input/output pin.); 1=ENET_COL (Ethernet Collision detect (MII interface).); 2=SD_DAT_1 (Data line 1 for SD card interface.); 3=PWM0_5 (Pulse Width Modulator 0, output 5.)
0xA0 P1_8 reset 0x30 — I/O configuration register for pin P1[8]
  [10] OD — Open-drain mode.
    values as P0_0.OD
  [9] SLEW — Driver slew rate
    values as P0_0.SLEW
  [6] INV — Invert input
    values as P0_0.INV
  [5] HYS — Hysteresis.
    0=DISABLE; 1=ENABLE
  [4:3] MODE — Selects function mode (on-chip pull-up/pull-down resistor control).
    values as P0_0.MODE
  [2:0] FUNC — Selects pin function for pin P1[8]
    0=P1_8 (General purpose digital input/output pin.); 1=ENET_CRS_CRS_DV (Ethernet Carrier Sense (MII interface) or Ethernet Carrier Sense/Data Valid (RMII interface).); 3=T3_MAT1 (Match output for Timer 3, channel 1.); 4=SSP2_SSEL (Slave Select for SSP2.)
